# nrf9220_secure register map
Vendor: Nordic Semiconductor; Series: nRF92; File version: 1
CPU: CM33 r0p4, little endian, MPU, no FPU, 3 interrupt priority bits, 480 interrupts, 8 SAU regions
Registers are 32-bit, read-write, reset 0x0 unless marked. A register's access mark holds for its fields unless they carry their own. Offsets are from the block's base; [hi:lo] are bit positions; lines under a group give offsets from that group; {n}, {i} and the like mark numbered series.

## AHBBUFFER_SEC_NS — AHB Buffer
Base 0x5F909000
Same registers: GLOBAL_AHBBUFFER_APP_NS 0x4F90A000, GLOBAL_AHBBUFFER_CELL_NS 0x4F90C000, GLOBAL_AHBBUFFER_APP_S 0x5F90A000, GLOBAL_AHBBUFFER_CELL_S 0x5F90C000
0x100 EVENTS_BUSERROR — Error response to posted write
  [0] EVENTS_BUSERROR
    0=NotGenerated (Event not generated); 1=Generated (Event generated)
0x200 SHORTS — Shortcuts between local events and tasks
0x300 INTEN — Enable or disable interrupt
  [0] BUSERROR — Enable or disable interrupt for event BUSERROR
    0=Disabled; 1=Enabled
0x304 INTENSET — Enable interrupt
  [0] BUSERROR — Write '1' to enable interrupt for event BUSERROR
    on read: 0=Disabled (Read: Disabled); 1=Enabled (Read: Enabled) | on write: 1=Set (Enable)
0x308 INTENCLR — Disable interrupt
  [0] BUSERROR — Write '1' to disable interrupt for event BUSERROR
    on read: 0=Disabled (Read: Disabled); 1=Enabled (Read: Enabled) | on write: 1=Clear (Disable)
0x30C INTPEND ro — Pending interrupts
  [0] BUSERROR — Read pending status of interrupt for event BUSERROR
    on read: 0=NotPending (Read: Not pending); 1=Pending (Read: Pending)
0x500 OPMODE — Operation mode
  [1:0] OPMODE
    0=f0 (Bypass); 1=f1 (Post all writes); 2=f2 (Obey hposted input); 3=f3 (Take OpMode from port)
0x504 ERRORADDRENABLE — Enable bit for error address tracking
  [0] ERRORADDRENABLE — Tracking must be enabled when it is needed. Detected error response for posted write (EVENT BUSERROR) will halt tracking and change the value of this register to 0.
    0=e0 (Error address is not tracked); 1=e1 (Error address is tracked)
0x508 ERRORADDR — Address for posted write error response
  [31:0] ERRORADDR — First address that caused error response for posted write. Valid only when EVENT BUSERROR is 1.

## IPCMAP_S — IPCMAP APB registers
Base 0x5F923000
{0x400+8i} CHANNEL[{i}] (i=0..30) group — Unspecified
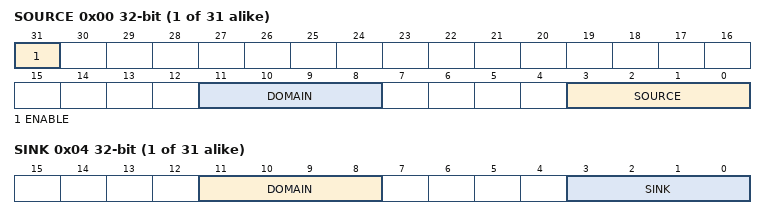
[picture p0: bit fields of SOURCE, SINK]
  0x00 SOURCE — Description cluster: The IPCT source configuration for the channel [n] from a ICPT.
    [31] ENABLE — Channel enable.
      0=Disabled (Disable channel.); 1=Enabled (Enable channel.)
    [11:8] DOMAIN — Domain identifier.
    [3:0] SOURCE — Source identification for IPC mapping.
  0x04 SINK — Description cluster: The IPCT sink configuration for the channel [n] to another ICPT.
    [11:8] DOMAIN — Domain identifier.
    [3:0] SINK — Sink identifiation for IPC mapping.

## IRQMAP_S — IRQMAP APB registers
Base 0x5F924000
{0x400+4i} IRQ[{i}] (i=0..479) group — Unspecified
  0x00 SINK — Description cluster: The interrupt sink configuration for interrupt [n] to a processor.
    [11:8] PROCESSORID — Processor identifier.

## GLOBAL_EGU130_NS — Event generator unit 0
Base 0x4F92D000
Same registers: GLOBAL_EGU130_S 0x5F92D000
{0x0+4i} TASKS_TRIGGER[{i}] (i=0..15) wo — Description collection: Trigger n for triggering the corresponding TRIGGERED[n] event
  [0] TASKS_TRIGGER — Trigger n for triggering the corresponding TRIGGERED[n] event
    1=Trigger task
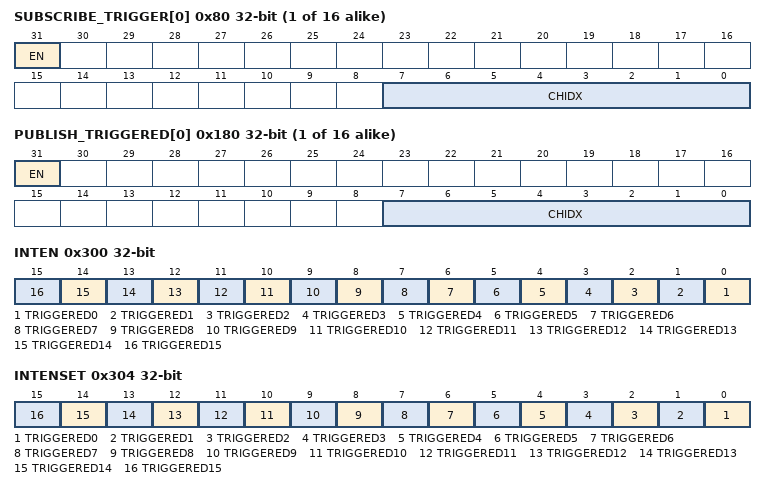
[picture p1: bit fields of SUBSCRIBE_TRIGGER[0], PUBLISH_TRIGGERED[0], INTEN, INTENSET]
{0x80+4i} SUBSCRIBE_TRIGGER[{i}] (i=0..15) — Description collection: Subscribe configuration for task TRIGGER[n]
  [31] EN
    0=Disabled (Disable subscription); 1=Enabled (Enable subscription)
  [7:0] CHIDX — DPPI channel that task TRIGGER[n] will subscribe to
{0x100+4i} EVENTS_TRIGGERED[{i}] (i=0..15) — Description collection: Event number n generated by triggering the corresponding TRIGGER[n] task
  [0] EVENTS_TRIGGERED — Event number n generated by triggering the corresponding TRIGGER[n] task
    0=NotGenerated (Event not generated); 1=Generated (Event generated)
{0x180+4i} PUBLISH_TRIGGERED[{i}] (i=0..15) — Description collection: Publish configuration for event TRIGGERED[n]
  [31] EN
    0=Disabled (Disable publishing); 1=Enabled (Enable publishing)
  [7:0] CHIDX — DPPI channel that event TRIGGERED[n] will publish to
0x300 INTEN — Enable or disable interrupt
  [all] fields
    0=Disabled; 1=Enabled
  [n] TRIGGERED{n} (n=0..15) — Enable or disable interrupt for event TRIGGERED[{n}]
0x304 INTENSET — Enable interrupt
  [all] fields
    on read: 0=Disabled (Read: Disabled); 1=Enabled (Read: Enabled) | on write: 1=Set (Enable)
  [n] TRIGGERED{n} (n=0..15) — Write '1' to enable interrupt for event TRIGGERED[{n}]
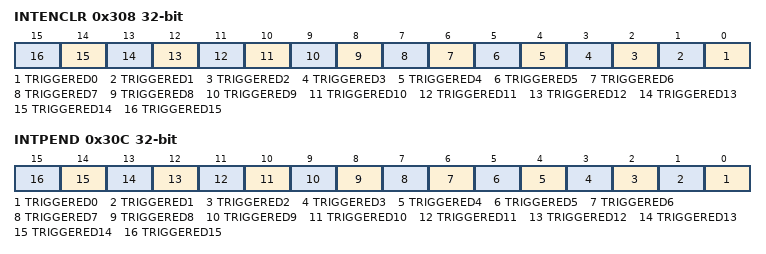
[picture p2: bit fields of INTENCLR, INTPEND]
0x308 INTENCLR — Disable interrupt
  [all] fields
    on read: 0=Disabled (Read: Disabled); 1=Enabled (Read: Enabled) | on write: 1=Clear (Disable)
  [n] TRIGGERED{n} (n=0..15) — Write '1' to disable interrupt for event TRIGGERED[{n}]
0x30C INTPEND ro — Pending interrupts
  [all] fields
    on read: 0=NotPending (Read: Not pending); 1=Pending (Read: Pending)
  [n] TRIGGERED{n} (n=0..15) — Read pending status of interrupt for event TRIGGERED[{n}]
